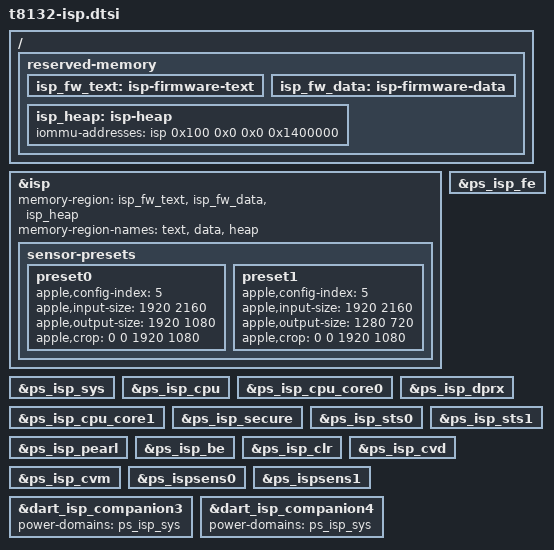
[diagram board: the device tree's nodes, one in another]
// SPDX-License-Identifier: GPL-2.0+ OR MIT
/*
 * The T8132 ISP's firmware handoff and the front camera's modes, as on
 * the J713.
 *
 * iBoot loads the ISP firmware outside the kernel's memory, at addresses
 * that move with the boot firmware. The boot loader fills these
 * placeholders from the ADT's isp segment-ranges: reg, and
 * iommu-addresses where the firmware runs them, from 0x100_0000_0000 on.
 * It then sets apple,platform-id from the ADT isp sensor-type, copies the
 * address filter windows of the ADT's ISP DART into apple,dapf-ranges and
 * enables the ISP and its DARTs. The driver checks that the coprocessor's reset
 * vector is this text before it starts the firmware.
 *
 * Copyright The Asahi Linux Contributors
 */

/ {
	reserved-memory {
		isp_fw_text: isp-firmware-text { };

		isp_fw_data: isp-firmware-data { };

		/* the firmware's 20 MiB main memory, the driver allocates above it */
		isp_heap: isp-heap {
			iommu-addresses = <&isp 0x100 0x0 0x0 0x1400000>;
		};
	};
};

&isp {
	memory-region = <&isp_fw_text>, <&isp_fw_data>, <&isp_heap>;
	memory-region-names = "text", "data", "heap";

	/* The 12 MP front camera, an IMX958: configuration 5, as on the J616s. */
	sensor-presets {
		/* 1920x1080 */
		preset0 {
			apple,config-index = <5>;
			apple,input-size = <1920 2160>;
			apple,output-size = <1920 1080>;
			apple,crop = <0 0 1920 1080>;
		};
		/* 1280x720: the same window as 1920x1080, scaled down */
		preset1 {
			apple,config-index = <5>;
			apple,input-size = <1920 2160>;
			apple,output-size = <1280 720>;
			apple,crop = <0 0 1920 1080>;
		};
	};
};

/* The camera powers the ISP from its first stream until it is unbound. */
&ps_isp_sys {
	status = "okay";
};

&ps_isp_cpu {
	status = "okay";
};

&ps_isp_cpu_core0 {
	status = "okay";
};

&ps_isp_cpu_core1 {
	status = "okay";
};

&ps_isp_fe {
	status = "okay";
};

&ps_isp_dprx {
	status = "okay";
};

&ps_isp_secure {
	status = "okay";
};

&ps_isp_sts0 {
	status = "okay";
};

&ps_isp_sts1 {
	status = "okay";
};

&ps_isp_pearl {
	status = "okay";
};

&ps_isp_be {
	status = "okay";
};

&ps_isp_clr {
	status = "okay";
};

&ps_isp_cvd {
	status = "okay";
};

&ps_isp_cvm {
	status = "okay";
};

&ps_ispsens0 {
	status = "okay";
};

&ps_ispsens1 {
	status = "okay";
};

/* The ISP companion DARTs sit in the ISP block, as the ISP DARTs do. */
&dart_isp_companion3 {
	power-domains = <&ps_isp_sys>;
};

&dart_isp_companion4 {
	power-domains = <&ps_isp_sys>;
};
